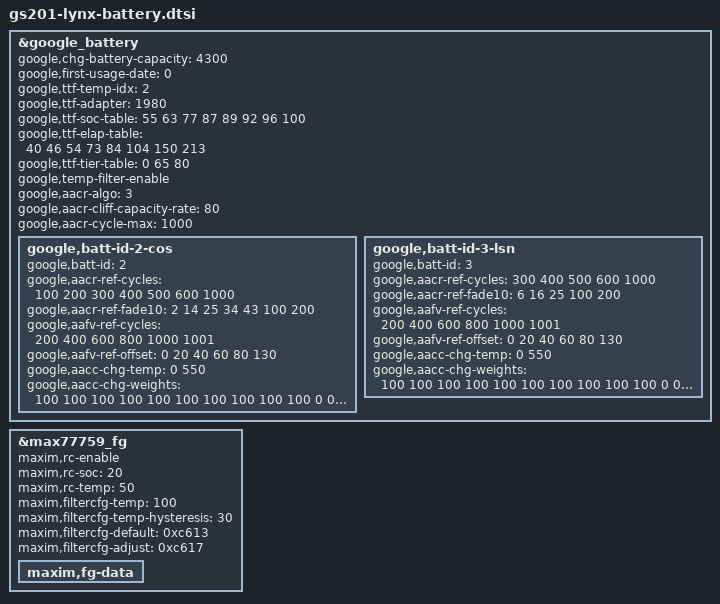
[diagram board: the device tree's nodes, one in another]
// SPDX-License-Identifier: GPL-2.0-only
/*
 * Battery device tree entries specific to raven
 *
 * Copyright 2022 Google,LLC
 *
 */

&google_battery {
	google,chg-battery-capacity = <4300>;
	google,first-usage-date = <0>;

	google,ttf-temp-idx= <2>;
	google,ttf-adapter = <1980>;
	google,ttf-soc-table =  <55 63 77 87 89  92  96 100>;
	google,ttf-elap-table = <40 46 54 73 84 104 150 213>;
	google,ttf-tier-table = <0 65 80>;

	google,temp-filter-enable;

	/* 90% after 600 cycles, 80% after 1000 cycles */
	google,aacr-algo = <3>;
	google,aacr-cliff-capacity-rate = <80>;
	google,aacr-cycle-max = <1000>;

	google,batt-id-2-cos {
		google,batt-id = <2>;
		google,aacr-ref-cycles = <100 200 300 400 500 600 1000>;
		google,aacr-ref-fade10 = <  2  14  25  34  43 100  200>;
		google,aafv-ref-cycles = <200 400 600 800 1000 1001>;
		google,aafv-ref-offset = <  0  20  40  60   80  130>;
		google,aacc-chg-temp = <0 550>;
		google,aacc-chg-weights = < /* units: 1/1000 cycles */
			100 100 100 100 100 100 100 100 100 100 /* soc:  1 ~  10, temp_idx: 0 */
			  0   0   0   0   0   0   0   0   0   0 /* soc: 11 ~  20, temp_idx: 0 */
			  0   0   0   0   0   0   0   0   0   0 /* soc: 21 ~  30, temp_idx: 0 */
			  0   0   0   0   0   0   0   0   0   0 /* soc: 31 ~  40, temp_idx: 0 */
			  0   0   0   0   0   0   0   0   0   0 /* soc: 41 ~  50, temp_idx: 0 */
			  0   0   0   0   0   0   0   0   0   0 /* soc: 51 ~  60, temp_idx: 0 */
			  0   0   0   0   0   0   0   0   0   0 /* soc: 61 ~  70, temp_idx: 0 */
			  0   0   0   0   0   0   0   0   0   0 /* soc: 71 ~  80, temp_idx: 0 */
			  0   0   0   0   0   0   0   0   0   0 /* soc: 81 ~  90, temp_idx: 0 */
			  0   0   0   0   0   0   0   0   0   0 /* soc: 91 ~ 100, temp_idx: 0 */
		>;
	};

	google,batt-id-3-lsn {
		google,batt-id = <3>;
		google,aacr-ref-cycles = <300 400 500 600 1000>;
		google,aacr-ref-fade10 = <  6  16  25 100  200>;
		google,aafv-ref-cycles = <200 400 600 800 1000 1001>;
		google,aafv-ref-offset = <  0  20  40  60   80  130>;
		google,aacc-chg-temp = <0 550>;
		google,aacc-chg-weights = < /* units: 1/1000 cycles */
			100 100 100 100 100 100 100 100 100 100 /* soc:  1 ~  10, temp_idx: 0 */
			  0   0   0   0   0   0   0   0   0   0 /* soc: 11 ~  20, temp_idx: 0 */
			  0   0   0   0   0   0   0   0   0   0 /* soc: 21 ~  30, temp_idx: 0 */
			  0   0   0   0   0   0   0   0   0   0 /* soc: 31 ~  40, temp_idx: 0 */
			  0   0   0   0   0   0   0   0   0   0 /* soc: 41 ~  50, temp_idx: 0 */
			  0   0   0   0   0   0   0   0   0   0 /* soc: 51 ~  60, temp_idx: 0 */
			  0   0   0   0   0   0   0   0   0   0 /* soc: 61 ~  70, temp_idx: 0 */
			  0   0   0   0   0   0   0   0   0   0 /* soc: 71 ~  80, temp_idx: 0 */
			  0   0   0   0   0   0   0   0   0   0 /* soc: 81 ~  90, temp_idx: 0 */
			  0   0   0   0   0   0   0   0   0   0 /* soc: 91 ~ 100, temp_idx: 0 */
		>;
	};
};

&max77759_fg {
	/delete-property/ maxim,force-batt-id;

	maxim,rc-enable;
	maxim,rc-soc = <20>;
	maxim,rc-temp = <50>;

	maxim,filtercfg-temp = <100>;
	maxim,filtercfg-temp-hysteresis = <30>;
	maxim,filtercfg-default = /bits/ 16 <0xc613>;
	maxim,filtercfg-adjust = /bits/ 16 <0xc617>;
	maxim,fg-data {
		#include "gs201-lynx-battery-data.dtsi"
	};
};
